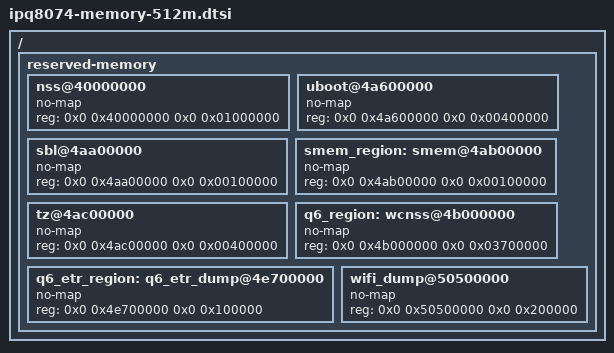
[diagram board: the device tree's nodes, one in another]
// SPDX-License-Identifier: GPL-2.0-only
/* Copyright (C) 2020 The Linux Foundation. All rights reserved.
 */

/ {
	reserved-memory {
		#address-cells = <2>;
		#size-cells = <2>;
		ranges;

		nss@40000000 {
			no-map;
			reg = <0x0 0x40000000 0x0 0x01000000>;
		};

		uboot@4a600000 {
			no-map;
			reg = <0x0 0x4a600000 0x0 0x00400000>;
		};

		sbl@4aa00000 {
			no-map;
			reg = <0x0 0x4aa00000 0x0 0x00100000>;
		};

		smem_region: smem@4ab00000 {
			no-map;
			reg = <0x0 0x4ab00000 0x0 0x00100000>;
		};

		tz@4ac00000 {
			no-map;
			reg = <0x0 0x4ac00000 0x0 0x00400000>;
		};

		q6_region: wcnss@4b000000 {
			no-map;
			reg = <0x0 0x4b000000 0x0 0x03700000>;
		};

		q6_etr_region: q6_etr_dump@4e700000 {
			no-map;
			reg = <0x0 0x4e700000 0x0 0x100000>;
		};

		wifi_dump@50500000 {
			no-map;
			reg = <0x0 0x50500000 0x0 0x200000>;
		};
	};
};
